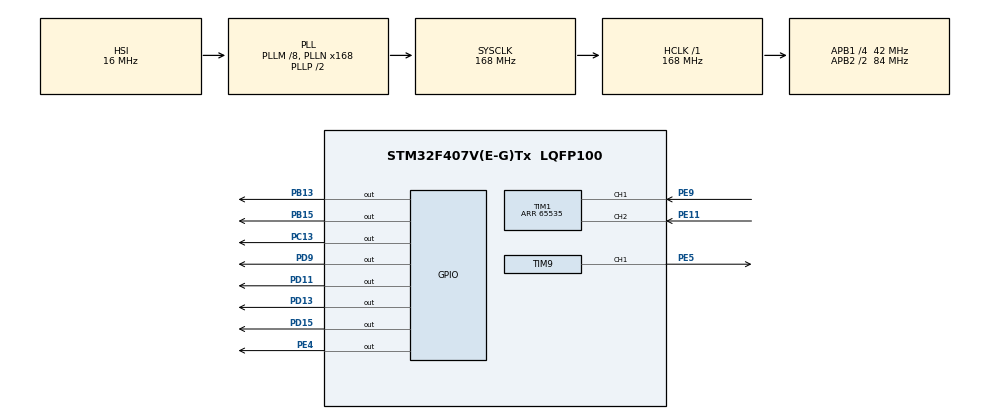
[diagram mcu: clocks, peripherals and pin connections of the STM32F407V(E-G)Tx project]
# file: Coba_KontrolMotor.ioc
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Mcu.Family=STM32F4
Mcu.Name=STM32F407V(E-G)Tx
Mcu.Package=LQFP100
NVIC.PriorityGroup=NVIC_PRIORITYGROUP_4
NVIC.TIM7_IRQn=true\:0\:0\:false\:false\:true\:true
PB13.Signal=GPIO_Output
PB15.Signal=GPIO_Output
PC13-ANTI_TAMP.Signal=GPIO_Output
PD11.Signal=GPIO_Output
PD13.Signal=GPIO_Output
PD15.Signal=GPIO_Output
PD9.Signal=GPIO_Output
PE11.Signal=S_TIM1_CH2
PE4.Signal=GPIO_Output
PE5.Signal=S_TIM9_CH1
PE9.Signal=S_TIM1_CH1
PH0-OSC_IN.Mode=HSE-External-Oscillator
PH0-OSC_IN.Signal=RCC_OSC_IN
PH1-OSC_OUT.Mode=HSE-External-Oscillator
PH1-OSC_OUT.Signal=RCC_OSC_OUT
ProjectManager.HeapSize=0x200
ProjectManager.StackSize=0x400
ProjectManager.TargetToolchain=TrueSTUDIO
RCC.48MHZClocksFreq_Value=84000000
RCC.AHBFreq_Value=168000000
RCC.APB1CLKDivider=RCC_HCLK_DIV4
RCC.APB1Freq_Value=42000000
RCC.APB1TimFreq_Value=84000000
RCC.APB2CLKDivider=RCC_HCLK_DIV2
RCC.APB2Freq_Value=84000000
RCC.APB2TimFreq_Value=168000000
RCC.CortexFreq_Value=168000000
RCC.HCLKFreq_Value=168000000
RCC.HSE_VALUE=8000000
RCC.HSI_VALUE=16000000
RCC.LSE_VALUE=32768
RCC.PLLM=8
RCC.PLLN=168
RCC.SYSCLKFreq_VALUE=168000000
RCC.SYSCLKSource=RCC_SYSCLKSOURCE_PLLCLK
RCC.VCOOutputFreq_Value=336000000
SH.S_TIM1_CH1.0=TIM1_CH1,Encoder_Interface
SH.S_TIM1_CH2.0=TIM1_CH2,Encoder_Interface
SH.S_TIM9_CH1.0=TIM9_CH1,PWM Generation1 CH1
TIM1.ClockDivision=TIM_CLOCKDIVISION_DIV1
TIM1.EncoderMode=TIM_ENCODERMODE_TI2
TIM1.Period=65535
TIM7.Period=4000
TIM7.Prescaler=840
TIM7.TIM_MasterOutputTrigger=TIM_TRGO_UPDATE
TIM9.Channel-PWM\ Generation1\ CH1=TIM_CHANNEL_1
TIM9.Period=100
TIM9.Prescaler=84
VP_TIM7_VS_ClockSourceINT.Mode=Enable_Timer
VP_TIM9_VS_ClockSourceINT.Mode=Internal
board=Coba_KontrolMotor

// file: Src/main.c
/**
  ******************************************************************************
  * File Name          : main.c
  * Description        : Main program body
  ******************************************************************************
  ** This notice applies to any and all portions of this file
  * that are not between comment pairs USER CODE BEGIN and
  * USER CODE END. Other portions of this file, whether
  * inserted by the user or by software development tools
  * are owned by their respective copyright owners.
  *
  * COPYRIGHT(c) 2018 STMicroelectronics
  *
  * Redistribution and use in source and binary forms, with or without modification,
  * are permitted provided that the following conditions are met:
  *   1. Redistributions of source code must retain the above copyright notice,
  *      this list of conditions and the following disclaimer.
  *   2. Redistributions in binary form must reproduce the above copyright notice,
  *      this list of conditions and the following disclaimer in the documentation
  *      and/or other materials provided with the distribution.
  *   3. Neither the name of STMicroelectronics nor the names of its contributors
  *      may be used to endorse or promote products derived from this software
  *      without specific prior written permission.
  *
  * THIS SOFTWARE IS PROVIDED BY THE COPYRIGHT HOLDERS AND CONTRIBUTORS "AS IS"
  * AND ANY EXPRESS OR IMPLIED WARRANTIES, INCLUDING, BUT NOT LIMITED TO, THE
  * IMPLIED WARRANTIES OF MERCHANTABILITY AND FITNESS FOR A PARTICULAR PURPOSE ARE
  * DISCLAIMED. IN NO EVENT SHALL THE COPYRIGHT HOLDER OR CONTRIBUTORS BE LIABLE
  * FOR ANY DIRECT, INDIRECT, INCIDENTAL, SPECIAL, EXEMPLARY, OR CONSEQUENTIAL
  * DAMAGES (INCLUDING, BUT NOT LIMITED TO, PROCUREMENT OF SUBSTITUTE GOODS OR
  * SERVICES; LOSS OF USE, DATA, OR PROFITS; OR BUSINESS INTERRUPTION) HOWEVER
  * CAUSED AND ON ANY THEORY OF LIABILITY, WHETHER IN CONTRACT, STRICT LIABILITY,
  * OR TORT (INCLUDING NEGLIGENCE OR OTHERWISE) ARISING IN ANY WAY OUT OF THE USE
  * OF THIS SOFTWARE, EVEN IF ADVISED OF THE POSSIBILITY OF SUCH DAMAGE.
  *
  ******************************************************************************
  */

#include "main.h"
#include "stm32f4xx_hal.h"
#include "STM_MY_LCD16X2.h"
#include "stdio.h"
#include "stdlib.h"
#include "math.h"
#include "string.h"

#define motor 	TIM9->CCR1
#define encoder TIM1->CNT

#define kp_motor 5
#define ki_motor 0.5
#define kd_motor 0.05

TIM_HandleTypeDef htim1;
TIM_HandleTypeDef htim7;
TIM_HandleTypeDef htim9;

/* USER CODE BEGIN PV */
/* Private variables ---------------------------------------------------------*/

/* USER CODE END PV */

void SystemClock_Config(void);
static void MX_GPIO_Init(void);
static void MX_TIM1_Init(void);
static void MX_TIM9_Init(void);
static void MX_TIM7_Init(void);

void HAL_TIM_MspPostInit(TIM_HandleTypeDef *htim);

/* USER CODE BEGIN PFP */
/* Private function prototypes -----------------------------------------------*/

/* USER CODE END PFP */

/* USER CODE BEGIN 0 */
short int v_motor, sp_motor;
float p_motor, i_motor, d_motor;
float error_motor, previous_error_motor, output_motor;

/* USER CODE END 0 */

int main(void)
{

  /* MCU Configuration----------------------------------------------------------*/

  /* Reset of all peripherals, Initializes the Flash interface and the Systick. */
  HAL_Init();

  /* Configure the system clock */
  SystemClock_Config();

  /* Initialize all configured peripherals */
  MX_GPIO_Init();
  MX_TIM1_Init();
  MX_TIM9_Init();
  MX_TIM7_Init();

  LCD1602_Begin4BIT(GPIOB, GPIO_PIN_13, GPIO_PIN_15, GPIOD, GPIO_PIN_9, GPIO_PIN_11, GPIO_PIN_13, GPIO_PIN_15);
  LCD1602_noCursor();
  LCD1602_noBlink();

  /* USER CODE BEGIN 2 */
  HAL_TIM_Encoder_Start(&htim1,TIM_CHANNEL_1);
  HAL_TIM_PWM_Start(&htim9,TIM_CHANNEL_1);
  HAL_TIM_Base_Start_IT(&htim7);

  /* USER CODE END 2 */

  /* Infinite loop */
  while (1)
  {
	  sp_motor = 0;

	  LCD1602_clear();

	  LCD1602_setCursor(1,1);
	  LCD1602_PrintInt(v_motor);

	  LCD1602_setCursor(1,8);
	  LCD1602_PrintInt(output_motor);

	  HAL_Delay(200);

  }

}

void HAL_TIM_PeriodElapsedCallback(TIM_HandleTypeDef *htim)
{
  if(htim->Instance==TIM7)
  {
	  v_motor = encoder;

	  encoder = 0;

	  error_motor = sp_motor - v_motor;

	  p_motor = kp_motor*error_motor;
	  i_motor += ki_motor*error_motor;
	  d_motor = kd_motor*(error_motor - previous_error_motor);

	  previous_error_motor = error_motor;

	  if(i_motor > 100) i_motor = 100;
	  else if(i_motor < -100) i_motor = -100;

	  output_motor = p_motor + i_motor + d_motor;

	  if(output_motor > 100) output_motor = 100;
	  else if(output_motor < -100) output_motor = -100;

	  if(output_motor > 0)
	  {
		  HAL_GPIO_WritePin(GPIOE,GPIO_PIN_4,SET);
		  HAL_GPIO_WritePin(GPIOC,GPIO_PIN_13,RESET);
	  }
	  else
	  {
		  HAL_GPIO_WritePin(GPIOE,GPIO_PIN_4,RESET);
		  HAL_GPIO_WritePin(GPIOC,GPIO_PIN_13,SET);
	  }

	  motor = abs(output_motor);
  }
}

/** System Clock Configuration
*/
void SystemClock_Config(void)
{

  RCC_OscInitTypeDef RCC_OscInitStruct;
  RCC_ClkInitTypeDef RCC_ClkInitStruct;

    /**Configure the main internal regulator output voltage
    */
  __HAL_RCC_PWR_CLK_ENABLE();

  __HAL_PWR_VOLTAGESCALING_CONFIG(PWR_REGULATOR_VOLTAGE_SCALE1);

    /**Initializes the CPU, AHB and APB busses clocks
    */
  RCC_OscInitStruct.OscillatorType = RCC_OSCILLATORTYPE_HSI;
  RCC_OscInitStruct.HSIState = RCC_HSI_ON;
  RCC_OscInitStruct.HSICalibrationValue = 16;
  RCC_OscInitStruct.PLL.PLLState = RCC_PLL_ON;
  RCC_OscInitStruct.PLL.PLLSource = RCC_PLLSOURCE_HSI;
  RCC_OscInitStruct.PLL.PLLM = 8;
  RCC_OscInitStruct.PLL.PLLN = 168;
  RCC_OscInitStruct.PLL.PLLP = RCC_PLLP_DIV2;
  RCC_OscInitStruct.PLL.PLLQ = 4;
  if (HAL_RCC_OscConfig(&RCC_OscInitStruct) != HAL_OK)
  {
    _Error_Handler(__FILE__, __LINE__);
  }

    /**Initializes the CPU, AHB and APB busses clocks
    */
  RCC_ClkInitStruct.ClockType = RCC_CLOCKTYPE_HCLK|RCC_CLOCKTYPE_SYSCLK
                              |RCC_CLOCKTYPE_PCLK1|RCC_CLOCKTYPE_PCLK2;
  RCC_ClkInitStruct.SYSCLKSource = RCC_SYSCLKSOURCE_PLLCLK;
  RCC_ClkInitStruct.AHBCLKDivider = RCC_SYSCLK_DIV1;
  RCC_ClkInitStruct.APB1CLKDivider = RCC_HCLK_DIV4;
  RCC_ClkInitStruct.APB2CLKDivider = RCC_HCLK_DIV2;

  if (HAL_RCC_ClockConfig(&RCC_ClkInitStruct, FLASH_LATENCY_5) != HAL_OK)
  {
    _Error_Handler(__FILE__, __LINE__);
  }

    /**Configure the Systick interrupt time
    */
  HAL_SYSTICK_Config(HAL_RCC_GetHCLKFreq()/1000);

    /**Configure the Systick
    */
  HAL_SYSTICK_CLKSourceConfig(SYSTICK_CLKSOURCE_HCLK);

  /* SysTick_IRQn interrupt configuration */
  HAL_NVIC_SetPriority(SysTick_IRQn, 0, 0);
}

/* TIM1 init function */
static void MX_TIM1_Init(void)
{

  TIM_Encoder_InitTypeDef sConfig;
  TIM_MasterConfigTypeDef sMasterConfig;

  htim1.Instance = TIM1;
  htim1.Init.Prescaler = 0;
  htim1.Init.CounterMode = TIM_COUNTERMODE_UP;
  htim1.Init.Period = 65535;
  htim1.Init.ClockDivision = TIM_CLOCKDIVISION_DIV1;
  htim1.Init.RepetitionCounter = 0;
  sConfig.EncoderMode = TIM_ENCODERMODE_TI2;
  sConfig.IC1Polarity = TIM_ICPOLARITY_RISING;
  sConfig.IC1Selection = TIM_ICSELECTION_DIRECTTI;
  sConfig.IC1Prescaler = TIM_ICPSC_DIV1;
  sConfig.IC1Filter = 0;
  sConfig.IC2Polarity = TIM_ICPOLARITY_RISING;
  sConfig.IC2Selection = TIM_ICSELECTION_DIRECTTI;
  sConfig.IC2Prescaler = TIM_ICPSC_DIV1;
  sConfig.IC2Filter = 0;
  if (HAL_TIM_Encoder_Init(&htim1, &sConfig) != HAL_OK)
  {
    _Error_Handler(__FILE__, __LINE__);
  }

  sMasterConfig.MasterOutputTrigger = TIM_TRGO_RESET;
  sMasterConfig.MasterSlaveMode = TIM_MASTERSLAVEMODE_DISABLE;
  if (HAL_TIMEx_MasterConfigSynchronization(&htim1, &sMasterConfig) != HAL_OK)
  {
    _Error_Handler(__FILE__, __LINE__);
  }

}

/* TIM7 init function */
static void MX_TIM7_Init(void)
{

  TIM_MasterConfigTypeDef sMasterConfig;

  htim7.Instance = TIM7;
  htim7.Init.Prescaler = 840;
  htim7.Init.CounterMode = TIM_COUNTERMODE_UP;
  htim7.Init.Period = 4000;
  if (HAL_TIM_Base_Init(&htim7) != HAL_OK)
  {
    _Error_Handler(__FILE__, __LINE__);
  }

  sMasterConfig.MasterOutputTrigger = TIM_TRGO_UPDATE;
  sMasterConfig.MasterSlaveMode = TIM_MASTERSLAVEMODE_DISABLE;
  if (HAL_TIMEx_MasterConfigSynchronization(&htim7, &sMasterConfig) != HAL_OK)
  {
    _Error_Handler(__FILE__, __LINE__);
  }

}

/* TIM9 init function */
static void MX_TIM9_Init(void)
{

  TIM_ClockConfigTypeDef sClockSourceConfig;
  TIM_OC_InitTypeDef sConfigOC;

  htim9.Instance = TIM9;
  htim9.Init.Prescaler = 84;
  htim9.Init.CounterMode = TIM_COUNTERMODE_UP;
  htim9.Init.Period = 100;
  htim9.Init.ClockDivision = TIM_CLOCKDIVISION_DIV1;
  if (HAL_TIM_Base_Init(&htim9) != HAL_OK)
  {
    _Error_Handler(__FILE__, __LINE__);
  }

  sClockSourceConfig.ClockSource = TIM_CLOCKSOURCE_INTERNAL;
  if (HAL_TIM_ConfigClockSource(&htim9, &sClockSourceConfig) != HAL_OK)
  {
    _Error_Handler(__FILE__, __LINE__);
  }

  if (HAL_TIM_PWM_Init(&htim9) != HAL_OK)
  {
    _Error_Handler(__FILE__, __LINE__);
  }

  sConfigOC.OCMode = TIM_OCMODE_PWM1;
  sConfigOC.Pulse = 0;
  sConfigOC.OCPolarity = TIM_OCPOLARITY_HIGH;
  sConfigOC.OCFastMode = TIM_OCFAST_DISABLE;
  if (HAL_TIM_PWM_ConfigChannel(&htim9, &sConfigOC, TIM_CHANNEL_1) != HAL_OK)
  {
    _Error_Handler(__FILE__, __LINE__);
  }

  HAL_TIM_MspPostInit(&htim9);

}

/** Configure pins as
        * Analog
        * Input
        * Output
        * EVENT_OUT
        * EXTI
*/
static void MX_GPIO_Init(void)
{

  GPIO_InitTypeDef GPIO_InitStruct;

  /* GPIO Ports Clock Enable */
  __HAL_RCC_GPIOE_CLK_ENABLE();
  __HAL_RCC_GPIOC_CLK_ENABLE();
  __HAL_RCC_GPIOH_CLK_ENABLE();
  __HAL_RCC_GPIOB_CLK_ENABLE();
  __HAL_RCC_GPIOD_CLK_ENABLE();

  /*Configure GPIO pin Output Level */
  HAL_GPIO_WritePin(GPIOE, GPIO_PIN_4, GPIO_PIN_RESET);

  /*Configure GPIO pin Output Level */
  HAL_GPIO_WritePin(GPIOC, GPIO_PIN_13, GPIO_PIN_RESET);

  /*Configure GPIO pin Output Level */
  HAL_GPIO_WritePin(GPIOB, GPIO_PIN_13|GPIO_PIN_15, GPIO_PIN_RESET);

  /*Configure GPIO pin Output Level */
  HAL_GPIO_WritePin(GPIOD, GPIO_PIN_9|GPIO_PIN_11|GPIO_PIN_13|GPIO_PIN_15, GPIO_PIN_RESET);

  /*Configure GPIO pin : PE4 */
  GPIO_InitStruct.Pin = GPIO_PIN_4;
  GPIO_InitStruct.Mode = GPIO_MODE_OUTPUT_PP;
  GPIO_InitStruct.Pull = GPIO_NOPULL;
  GPIO_InitStruct.Speed = GPIO_SPEED_FREQ_LOW;
  HAL_GPIO_Init(GPIOE, &GPIO_InitStruct);

  /*Configure GPIO pin : PC13 */
  GPIO_InitStruct.Pin = GPIO_PIN_13;
  GPIO_InitStruct.Mode = GPIO_MODE_OUTPUT_PP;
  GPIO_InitStruct.Pull = GPIO_NOPULL;
  GPIO_InitStruct.Speed = GPIO_SPEED_FREQ_LOW;
  HAL_GPIO_Init(GPIOC, &GPIO_InitStruct);

  /*Configure GPIO pins : PB13 PB15 */
  GPIO_InitStruct.Pin = GPIO_PIN_13|GPIO_PIN_15;
  GPIO_InitStruct.Mode = GPIO_MODE_OUTPUT_PP;
  GPIO_InitStruct.Pull = GPIO_NOPULL;
  GPIO_InitStruct.Speed = GPIO_SPEED_FREQ_LOW;
  HAL_GPIO_Init(GPIOB, &GPIO_InitStruct);

  /*Configure GPIO pins : PD9 PD11 PD13 PD15 */
  GPIO_InitStruct.Pin = GPIO_PIN_9|GPIO_PIN_11|GPIO_PIN_13|GPIO_PIN_15;
  GPIO_InitStruct.Mode = GPIO_MODE_OUTPUT_PP;
  GPIO_InitStruct.Pull = GPIO_NOPULL;
  GPIO_InitStruct.Speed = GPIO_SPEED_FREQ_LOW;
  HAL_GPIO_Init(GPIOD, &GPIO_InitStruct);

}

void _Error_Handler(char * file, int line)
{
  while(1)
  {
  }
}

/************************ (C) COPYRIGHT STMicroelectronics *****END OF FILE****/
